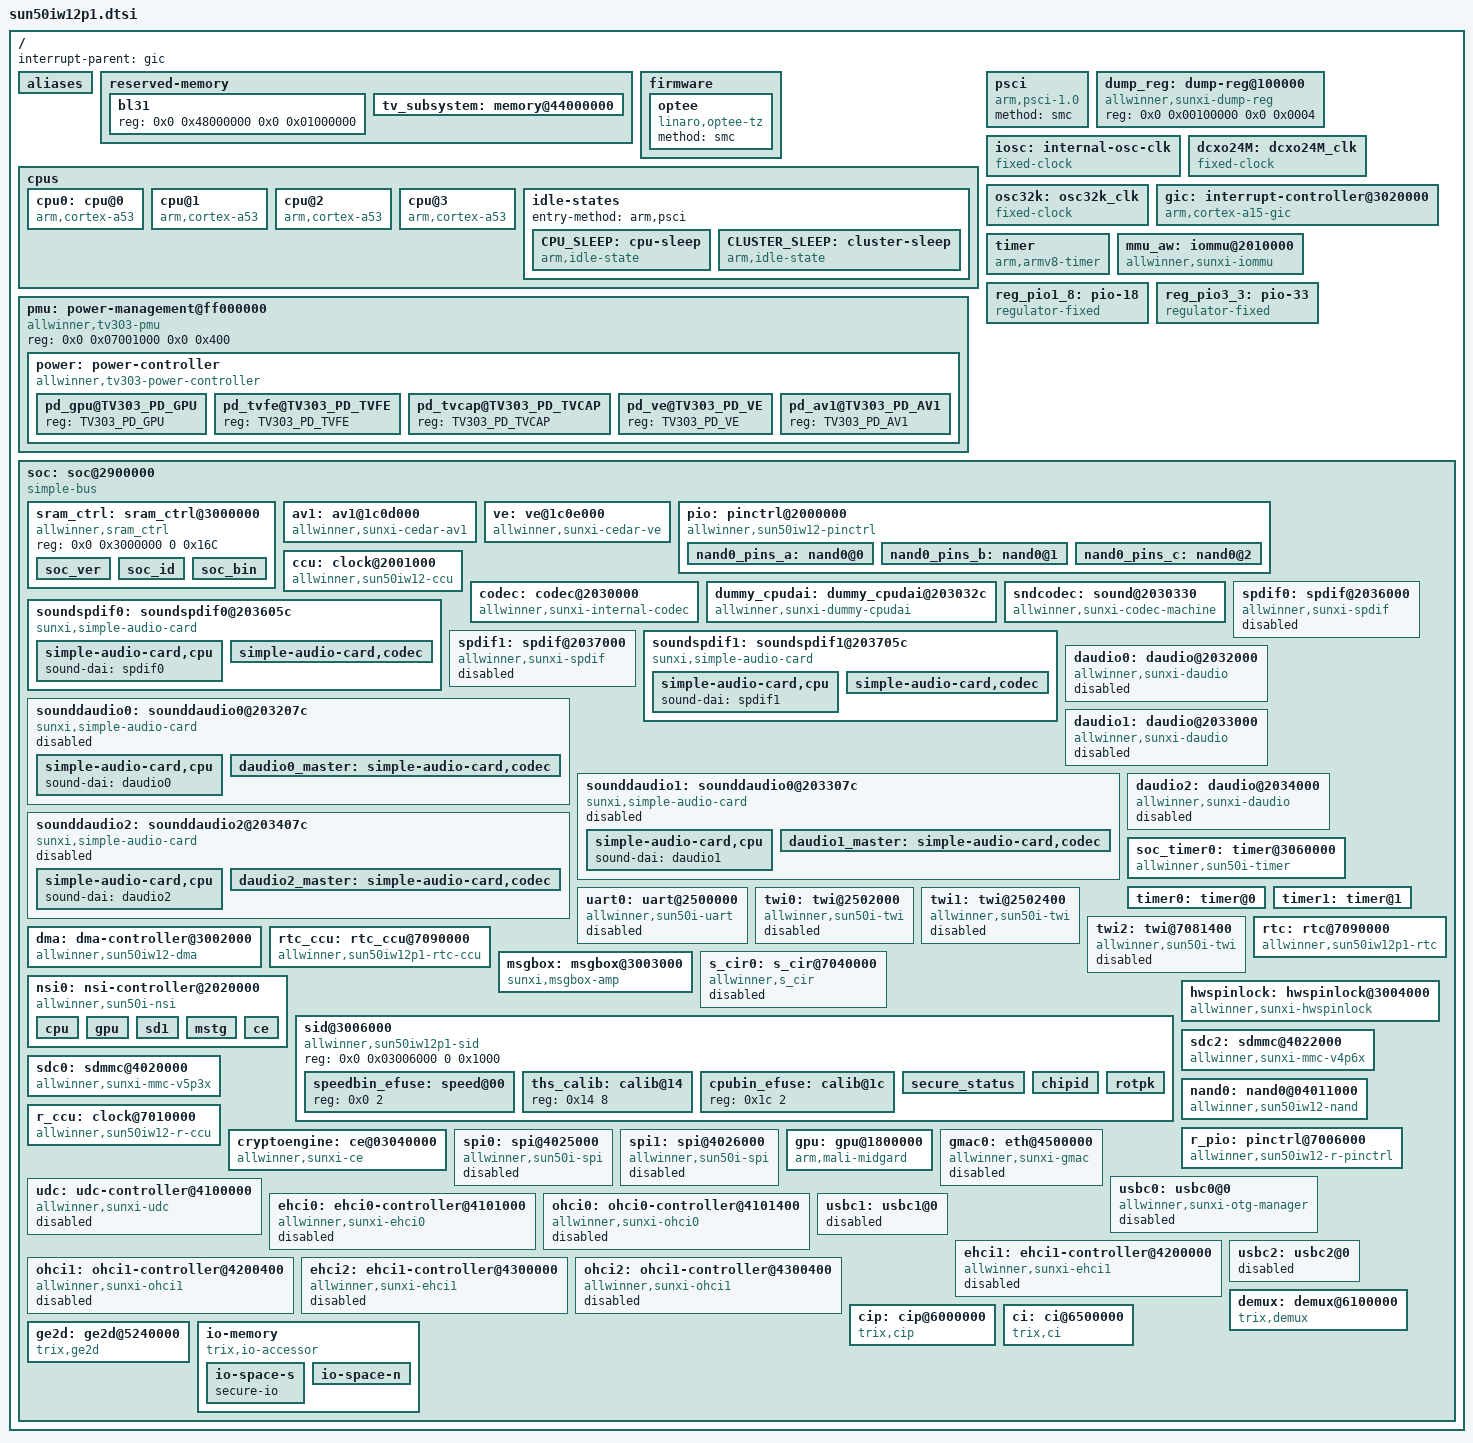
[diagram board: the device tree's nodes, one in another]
// SPDX-License-Identifier: (GPL-2.0+ or MIT)
/*
 * Copyright (C) 2020 frank@allwinnertech.com
 */

/dts-v1/;

#include <dt-bindings/clock/sun50iw12-ccu.h>
#include <dt-bindings/clock/sun50iw12-r-ccu.h>
#include <dt-bindings/clock/sun50iw12-rtc.h>
#include <dt-bindings/gpio/gpio.h>
#include <dt-bindings/gpio/sun4i-gpio.h>
#include <dt-bindings/interrupt-controller/arm-gic.h>
#include <dt-bindings/reset/sun50iw12-ccu.h>
#include <dt-bindings/reset/sun50iw12-r-ccu.h>
#include <dt-bindings/power/tv303-power.h>

/ {
	interrupt-parent = <&gic>;
	#address-cells = <2>;
	#size-cells = <2>;

	aliases {
		spi0 = &spi0;
		spi1 = &spi1;
		twi0 = &twi0;
		twi1 = &twi1;
		twi2 = &twi2;
		nand0 =&nand0;
		global-timer0  = &soc_timer0;
		ir0  = &s_cir0;
	};

	reserved-memory {
		#address-cells = <2>;
		#size-cells = <2>;
		ranges;

		bl31 {
			reg = <0x0 0x48000000 0x0 0x01000000>;
		};

		tv_subsystem: memory@44000000 {
			reg = <0x0 0x44000000 0x0 0x04000000>;
			no-map;
		};
	};

	firmware {
		optee {
			compatible = "linaro,optee-tz";
			method = "smc";
		};
	};

	cpus {
		#address-cells = <2>;
		#size-cells = <0>;

		cpu0: cpu@0 {
			device_type = "cpu";
			compatible = "arm,cortex-a53","arm,armv8";
			reg = <0x0 0x0>;
			enable-method = "psci";
			cpu-idle-states = <&CPU_SLEEP &CLUSTER_SLEEP>;
		};

		cpu@1 {
			device_type = "cpu";
			compatible = "arm,cortex-a53","arm,armv8";
			reg = <0x0 0x1>;
			enable-method = "psci";
			cpu-idle-states = <&CPU_SLEEP &CLUSTER_SLEEP>;
		};

		cpu@2 {
			device_type = "cpu";
			compatible = "arm,cortex-a53","arm,armv8";
			reg = <0x0 0x2>;
			enable-method = "psci";
			cpu-idle-states = <&CPU_SLEEP &CLUSTER_SLEEP>;
		};

		cpu@3 {
			device_type = "cpu";
			compatible = "arm,cortex-a53","arm,armv8";
			reg = <0x0 0x3>;
			enable-method = "psci";
			cpu-idle-states = <&CPU_SLEEP &CLUSTER_SLEEP>;
		};

		idle-states {
			entry-method = "arm,psci";

			CPU_SLEEP: cpu-sleep {
				compatible = "arm,idle-state";
				arm,psci-suspend-param = <0x0010000>;
				entry-latency-us = <46>;
				exit-latency-us = <59>;
				min-residency-us = <110000>;
				local-timer-stop;
			};

			CLUSTER_SLEEP: cluster-sleep {
				compatible = "arm,idle-state";
				arm,psci-suspend-param = <0x1010000>;
				entry-latency-us = <47>;
				exit-latency-us = <74>;
				min-residency-us = <160000>;
				local-timer-stop;
			};
		};
	};

	psci {
		compatible = "arm,psci-1.0";
		method = "smc";
	};

	dump_reg: dump-reg@100000 {
		compatible = "allwinner,sunxi-dump-reg";
		reg = <0x0 0x00100000 0x0 0x0004>;
	};

	iosc: internal-osc-clk {
		#clock-cells = <0>;
		compatible = "fixed-clock";
		clock-frequency = <16000000>;
		clock-accuracy = <300000000>;
		clock-output-names = "iosc";
	};

	dcxo24M: dcxo24M_clk {
		#clock-cells = <0>;
		compatible = "fixed-clock";
		clock-frequency = <24000000>;
		clock-output-names = "dcxo24M";
	};

	osc32k: osc32k_clk {
		#clock-cells = <0>;
		compatible = "fixed-clock";
		clock-frequency = <32768>;
		clock-output-names = "osc32k";
	};

	gic: interrupt-controller@3020000 {
		compatible = "arm,cortex-a15-gic", "arm,cortex-a9-gic";
		#interrupt-cells = <3>;
		#address-cells = <0>;
		interrupt-controller;
		reg = <0x0 0x03021000 0 0x1000>, /* GIC Dist */
		      <0x0 0x03022000 0 0x2000>, /* GIC CPU */
		      <0x0 0x03024000 0 0x2000>, /* GIC VCPU Control */
		      <0x0 0x03026000 0 0x2000>; /* GIC VCPU */
		interrupts = <GIC_PPI 9 0xf04>;  /* GIC Maintenence IRQ */
		interrupt-parent = <&gic>;
	};

	timer {
		compatible = "arm,armv8-timer";
		interrupts = <GIC_PPI 13
			(GIC_CPU_MASK_SIMPLE(4) | IRQ_TYPE_LEVEL_HIGH)>,
			     <GIC_PPI 14
			(GIC_CPU_MASK_SIMPLE(4) | IRQ_TYPE_LEVEL_HIGH)>,
			     <GIC_PPI 11
			(GIC_CPU_MASK_SIMPLE(4) | IRQ_TYPE_LEVEL_HIGH)>,
			     <GIC_PPI 10
			(GIC_CPU_MASK_SIMPLE(4) | IRQ_TYPE_LEVEL_HIGH)>;
		arm,no-tick-in-suspend;
	};

	mmu_aw: iommu@2010000 {
		compatible = "allwinner,sunxi-iommu";
		reg = <0x0 0x02010000 0x0 0x1000>;
		interrupts = <GIC_SPI 71 IRQ_TYPE_LEVEL_HIGH>;
		interrupt-names = "iommu-irq";
		clocks = <&ccu CLK_BUS_IOMMU>;
		clock-names = "iommu";
		#iommu-cells = <2>;
	};

	pmu: power-management@ff000000 {
		compatible = "allwinner,tv303-pmu", "syscon", "simple-mfd";
		reg = <0x0 0x07001000 0x0 0x400>;

		power: power-controller {
			compatible = "allwinner,tv303-power-controller";
			clocks = <&r_ccu CLK_R_APB1_BUS_PPU>;
			clock-names = "ppu";
			resets = <&r_ccu RST_R_APB1_BUS_PPU>;
			reset-names = "ppu_rst";
			#power-domain-cells = <1>;
			#address-cells = <1>;
			#size-cells = <0>;

			/* These power domains are grouped by VD_LOGIC */
			pd_gpu@TV303_PD_GPU {
				reg = <TV303_PD_GPU>;
			};
			pd_tvfe@TV303_PD_TVFE {
				reg = <TV303_PD_TVFE>;
			};
			pd_tvcap@TV303_PD_TVCAP {
				reg = <TV303_PD_TVCAP>;
			};
			pd_ve@TV303_PD_VE {
				reg = <TV303_PD_VE>;
			};
			pd_av1@TV303_PD_AV1 {
				reg = <TV303_PD_AV1>;
			};
		};
	};

	reg_pio1_8: pio-18 {
		compatible = "regulator-fixed";
		regulator-name = "pio-18";
		regulator-min-microvolt = <1800000>;
		regulator-max-microvolt = <1800000>;
	};

	reg_pio3_3: pio-33 {
		compatible = "regulator-fixed";
		regulator-name = "pio-33";
		regulator-min-microvolt = <3300000>;
		regulator-max-microvolt = <3300000>;
	};

	soc: soc@2900000 {
		compatible = "simple-bus";
		#address-cells = <2>;
		#size-cells = <2>;
		ranges;

		sram_ctrl: sram_ctrl@3000000 {
			compatible = "allwinner,sram_ctrl";
			reg = <0x0 0x3000000 0 0x16C>;
			soc_ver {
				offset = <0x24>;
				mask = <0x7>;
				shift = <0>;
				ver_a = <0x18600000>;
			};

			soc_id {
				offset = <0x200>;
				mask = <0x1>;
				shift = <22>;
			};

			soc_bin {
				offset = <0x0>;
				mask = <0x3ff>;
				shift = <0x0>;
			};

		};

		av1: av1@1c0d000 {
			compatible = "allwinner,sunxi-cedar-av1";
			reg = <0x0 0x01c0d000 0x0 0x1000>,
			      <0x0 0x02001000 0x0 0x1000>;
			interrupts = <GIC_SPI 107 IRQ_TYPE_LEVEL_HIGH>;
			clocks = <&ccu CLK_BUS_VE>,
				 <&ccu CLK_BUS_AV1>,
				 <&ccu CLK_VE_CORE>,
				 <&ccu CLK_MBUS_AV1>;
			clock-names = "bus_ve", "bus_av1", "av1", "mbus_av1";
			resets = <&ccu RST_BUS_VE>,
				 <&ccu RST_BUS_AV1>;
			reset-names = "reset_ve", "reset_av1";
			iommus = <&mmu_aw 5 1>;
		};

		ve: ve@1c0e000 {
			compatible = "allwinner,sunxi-cedar-ve";
			reg = <0x0 0x01c0e000 0x0 0x1000>,
			      <0x0 0x03000000 0x0 0x10>;
			interrupts = <GIC_SPI 75 IRQ_TYPE_LEVEL_HIGH>;
			clocks = <&ccu CLK_BUS_VE>,
				 <&ccu CLK_BUS_VE3>,
				 <&ccu CLK_VE_CORE>,
				 <&ccu CLK_MBUS_VE3>;
			clock-names = "bus_ve", "bus_ve3", "ve", "mbus_ve3";
			resets = <&ccu RST_BUS_VE>,
				 <&ccu RST_BUS_VE3>;
			reset-names = "reset_ve", "reset_ve3";
			iommus = <&mmu_aw 0 1>;
		};

		pio: pinctrl@2000000 {
			compatible = "allwinner,sun50iw12-pinctrl";
			reg = <0x0 0x02000000 0x0 0x400>;
			interrupts = <GIC_SPI 54 IRQ_TYPE_LEVEL_HIGH>,
				     <GIC_SPI 55 IRQ_TYPE_LEVEL_HIGH>,
				     <GIC_SPI 56 IRQ_TYPE_LEVEL_HIGH>,
				     <GIC_SPI 57 IRQ_TYPE_LEVEL_HIGH>,
				     <GIC_SPI 58 IRQ_TYPE_LEVEL_HIGH>,
				     <GIC_SPI 59 IRQ_TYPE_LEVEL_HIGH>,
				     <GIC_SPI 60 IRQ_TYPE_LEVEL_HIGH>,
				     <GIC_SPI 61 IRQ_TYPE_LEVEL_HIGH>,
				     <GIC_SPI 62 IRQ_TYPE_LEVEL_HIGH>;
			clocks = <&ccu CLK_APB0>, <&dcxo24M>, <&osc32k>;
			clock-names = "apb", "hosc", "losc";
			gpio-controller;
			#gpio-cells = <3>;
			interrupt-controller;
			#interrupt-cells = <3>;
			vcc-pf-supply = <&reg_pio1_8>;
			vcc-pfo-supply = <&reg_pio3_3>;

			nand0_pins_a: nand0@0 {
				pins = "PC0", "PC1", "PC2", "PC5",
						 "PC8", "PC9", "PC10", "PC11",
						 "PC12", "PC13", "PC14", "PC15",
						 "PC16";
				function = "nand0";
				drive-strength = <30>;
			};

			nand0_pins_b: nand0@1 {
				pins = "PC4", "PC6", "PC3", "PC7";
				function = "nand0";
				drive-strength = <30>;
				bias-pull-up;/* only RB&CE should be pulled up */
			};

			nand0_pins_c: nand0@2 {
				pins = "PC0", "PC1", "PC2", "PC3",
						 "PC4", "PC5", "PC6", "PC7",
						 "PC8", "PC9", "PC10", "PC11",
						 "PC12", "PC13", "PC14", "PC15",
						 "PC16";
				function = "gpio_in";
			};
		};

		ccu: clock@2001000 {
			compatible = "allwinner,sun50iw12-ccu";
			reg = <0x0 0x02001000 0x0 0x1000>;
			clocks = <&dcxo24M>, <&osc32k>, <&iosc>;
			clock-names = "hosc", "losc", "iosc";
			#clock-cells = <1>;
			#reset-cells = <1>;
		};

		/* codec addr: 0x02030000, the others is invalid to avoid build warining */
		codec:codec@2030000 {
			#sound-dai-cells = <0>;
			compatible = "allwinner,sunxi-internal-codec";
			reg = <0x0 0x02030000 0x0 0x32c>,/*codec baseadress*/
			      <0x0 0x02031000 0x0 0x7c>;/*interi2s baseadress*/
			clocks = <&ccu CLK_PLL_AUDIO>,	/* 98.304M / 90.3168M */
				 <&ccu CLK_AUDIO_CODEC_DAC>,
				 <&ccu CLK_AUDIO_CODEC_ADC>,
				 <&ccu CLK_BUS_AUDIO_CODEC>;
			clock-names = "pll_audio", "codec_dac", "codec_adc",
				      "codec_bus";
			resets = <&ccu RST_BUS_AUDIO_CODEC>;
			playback_cma	= <128>;
			capture_cma	= <256>;
			device_type = "codec";
		};

		dummy_cpudai:dummy_cpudai@203032c {
			compatible = "allwinner,sunxi-dummy-cpudai";
			reg = <0x0 0x0203032c 0x0 0x4>;
			tx_fifo_size	= <128>;
			rx_fifo_size	= <256>;
			dac_txdata	= <0x02030020>;
			adc_txdata	= <0x02030040>;
			playback_cma	= <128>;
			capture_cma	= <256>;
			device_type = "cpudai";
			dmas = <&dma 7>, <&dma 7>;
			dma-names = "tx", "rx";
		};

		sndcodec:sound@2030330 {
			compatible = "allwinner,sunxi-codec-machine";
			reg = <0x0 0x02030330 0x0 0x4>;
			interrupts = <GIC_SPI 25 IRQ_TYPE_LEVEL_HIGH>;
			hp_detect_case = <0x00>;
			sunxi,audio-codec = <&codec>;
			sunxi,cpudai-controller = <&dummy_cpudai>;
			device_type = "sndcodec";
		};

		/* spdif0 addr: 0x02036000, the others is invalid to avoid build warining */
		spdif0:spdif@2036000{
			#sound-dai-cells = <0>;
			compatible = "allwinner,sunxi-spdif";
			reg = <0x0 0x02036000 0x0 0x58>;
			clocks = <&ccu CLK_PLL_AUDIO>,	/* 98.304M / 90.3168M */
				 <&ccu CLK_SPDIF0_TX>,
				 <&ccu CLK_SPDIF0_RX>,
				 <&ccu CLK_BUS_SPDIF0>;
			clock-names = "pll_audio", "spdif_tx", "spdif_rx", "spdif_bus";
			resets = <&ccu RST_BUS_SPDIF0>;
			interrupts = <GIC_SPI 23 IRQ_TYPE_LEVEL_HIGH>;
			pinctrl-names = "default","sleep";
			device_type = "spdif0";
			dmas = <&dma 2>, <&dma 2>;
			dma-names = "tx", "rx";
			status = "disabled";
		};

		/* HDMI RX */
		soundspdif0:soundspdif0@203605c {
			reg = <0x0 0x0203605c 0x0 0x4>;
			compatible = "sunxi,simple-audio-card";
			simple-audio-card,name = "sndspdif0";
			 /* simple-audio-card,format = "i2s"; */
			simple-audio-card,cpu {
				sound-dai = <&spdif0>;
			};

			simple-audio-card,codec {
				/*snd-soc-dummy*/
			};
		 };

		/* spdif1 addr: 0x02037000, the others is invalid to avoid build warining */
		spdif1:spdif@2037000{
			#sound-dai-cells = <0>;
			compatible = "allwinner,sunxi-spdif";
			reg = <0x0 0x02037000 0x0 0x58>;
			clocks = <&ccu CLK_PLL_AUDIO>,	/* 98.304M / 90.3168M */
				 <&ccu CLK_SPDIF1_TX>,
				 <&ccu CLK_SPDIF1_RX>,
				 <&ccu CLK_BUS_SPDIF1>;
			clock-names = "pll_audio", "spdif_tx", "spdif_rx", "spdif_bus";
			resets = <&ccu RST_BUS_SPDIF1>;
			interrupts = <GIC_SPI 24 IRQ_TYPE_LEVEL_HIGH>;
			pinctrl-names = "default","sleep";
			device_type = "spdif1";
			dmas = <&dma 9>, <&dma 9>;
			dma-names = "tx", "rx";
			status = "disabled";
		};

		/* COMMOM USE */
		soundspdif1:soundspdif1@203705c {
			reg = <0x0 0x0203705c 0x0 0x4>;
			compatible = "sunxi,simple-audio-card";
			simple-audio-card,name = "sndspdif1";
			/* simple-audio-card,format = "i2s"; */
			simple-audio-card,cpu {
				sound-dai = <&spdif1>;
			};

			simple-audio-card,codec {
				/*snd-soc-dummy*/
			};
		 };

		/* daudio0 addr: 0x02032000, the others is invalid to avoid build warining */
		daudio0:daudio@2032000 {
			#sound-dai-cells = <0>;
			compatible = "allwinner,sunxi-daudio";
			reg = <0x0 0x02032000 0x0 0x7c>;
			clocks = <&ccu CLK_PLL_AUDIO>, /* 98.304M / 90.3168M */
				 <&ccu CLK_I2S0>,
				 <&ccu CLK_BUS_I2S0>;
			clock-names = "pll_audio", "i2s0", "i2s0_bus";
			resets = <&ccu RST_BUS_I2S0>;
			pinctrl-names = "default", "sleep";
			device_type = "daudio0";
			dmas = <&dma 3>, <&dma 3>;
			dma-names = "tx", "rx";
			status = "disabled";
		};

		sounddaudio0: sounddaudio0@203207c {
			reg = <0x0 0x0203207c 0x0 0x4>;
			compatible = "sunxi,simple-audio-card";
			simple-audio-card,name = "snddaudio0";
			simple-audio-card,format = "i2s";
			/* simple-audio-card,frame-master = <&daudio0_master>; */
			/* simple-audio-card,bitclock-master = <&daudio0_master>; */
			/* simple-audio-card,bitclock-inversion; */
			/* simple-audio-card,frame-inversion; */
			status = "disabled";
			simple-audio-card,cpu {
				sound-dai = <&daudio0>;
			};
			daudio0_master: simple-audio-card,codec {
				/* sound-dai = <&ac108>; */
			};
		};

		/* daudio1 addr: 0x02033000, the others is invalid to avoid build warining */
		daudio1:daudio@2033000 {
			#sound-dai-cells = <0>;
			compatible = "allwinner,sunxi-daudio";
			reg = <0x0 0x02033000 0x0 0x7c>;
			clocks = <&ccu CLK_PLL_AUDIO>, /* 98.304M / 90.3168M */
				 <&ccu CLK_I2S1>,
				 <&ccu CLK_BUS_I2S1>;
			clock-names = "pll_audio", "i2s1", "i2s1_bus";
			resets = <&ccu RST_BUS_I2S1>;
			pinctrl-names = "default", "sleep";
			device_type = "daudio1";
			dmas = <&dma 4>, <&dma 4>;
			dma-names = "tx", "rx";
			status = "disabled";
		};

		sounddaudio1: sounddaudio0@203307c {
			reg = <0x0 0x0203307c 0x0 0x4>;
			compatible = "sunxi,simple-audio-card";
			simple-audio-card,name = "snddaudio1";
			simple-audio-card,format = "i2s";
			status = "disabled";
			simple-audio-card,cpu {
				sound-dai = <&daudio1>;
			};
			daudio1_master: simple-audio-card,codec {
				/* sound-dai = <&ac108>; */
			};
		};

		/* daudio2 addr: 0x02034000, the others is invalid to avoid build warining */
		daudio2:daudio@2034000 {
			#sound-dai-cells = <0>;
			compatible = "allwinner,sunxi-daudio";
			reg = <0x0 0x02034000 0x0 0x7c>;
			clocks = <&ccu CLK_PLL_AUDIO>, /* 98.304M / 90.3168M */
				 <&ccu CLK_I2S2>,
				 <&ccu CLK_BUS_I2S2>;
			clock-names = "pll_audio", "i2s2", "i2s2_bus";
			resets = <&ccu RST_BUS_I2S2>;
			pinctrl-names = "default", "sleep";
			device_type = "daudio2";
			dmas = <&dma 5>, <&dma 5>;
			dma-names = "tx", "rx";
			status = "disabled";
		};

		sounddaudio2: sounddaudio2@203407c {
			reg = <0x0 0x0203407c 0x0 0x4>;
			compatible = "sunxi,simple-audio-card";
			simple-audio-card,name = "snddaudio2";
			simple-audio-card,format = "i2s";
			status = "disabled";
			simple-audio-card,cpu {
				sound-dai = <&daudio2>;
			};
			daudio2_master: simple-audio-card,codec {
				 /* snd-soc-dummy */
			};
		 };

		soc_timer0: timer@3060000 {
			compatible = "allwinner,sun50i-timer";
			device_type = "soc_timer";
			reg = <0x0 0x03060000 0x0 0xA0>;
			interrupt-parent = <&gic>;
			interrupts = <GIC_SPI 48 IRQ_TYPE_LEVEL_HIGH>;
			sunxi-timers = <&timer0>, <&timer1>;
		};

		timer0: timer@0 {
			clocks = <&dcxo24M>, <&ccu CLK_TIMER0>, <&ccu CLK_BUS_TIMER0>;
			clock-names = "parent", "mod", "bus";
			resets = <&ccu RST_BUS_TIMER0>;
		};

		timer1: timer@1 {
			clocks = <&dcxo24M>, <&ccu CLK_TIMER1>, <&ccu CLK_BUS_TIMER0>;
			clock-names = "parent", "mod", "bus";
		};

		uart0: uart@2500000 {
			compatible = "allwinner,sun50i-uart";
			reg = <0x0 0x02500000 0x0 0x400>;
			interrupts = <GIC_SPI 0 IRQ_TYPE_LEVEL_HIGH>;
			clocks = <&ccu CLK_BUS_UART0>;
			/* TODO add resets */
			uart0_port = <0>;
			uart0_type = <2>;
			status = "disabled";
		};

		twi0: twi@2502000{
			#address-cells = <1>;
			#size-cells = <0>;
			compatible = "allwinner,sun50i-twi";
			device_type = "twi0";
			reg = <0x0 0x02502000 0x0 0x400>;
			interrupts = <GIC_SPI 7 IRQ_TYPE_LEVEL_HIGH>;
			clocks = <&ccu CLK_BUS_I2C0>;
			resets = <&ccu RST_BUS_I2C0>;
			clock-names = "bus";
			status = "disabled";
		};

		twi1: twi@2502400{
			#address-cells = <1>;
			#size-cells = <0>;
			compatible = "allwinner,sun50i-twi";
			device_type = "twi1";
			reg = <0x0 0x2502400 0x0 0x400>;
			interrupts = <GIC_SPI 8 IRQ_TYPE_LEVEL_HIGH>;
			clocks = <&ccu CLK_BUS_I2C1>;
			resets = <&ccu RST_BUS_I2C1>;
			clock-names = "bus";
			status = "disabled";
		};

		twi2: twi@7081400{
			#address-cells = <1>;
			#size-cells = <0>;
			compatible = "allwinner,sun50i-twi";
			device_type = "s_twi0";
			reg = <0x0 0x07081400 0x0 0x400>;
			interrupts = <GIC_SPI 153 IRQ_TYPE_LEVEL_HIGH>;
			clocks = <&ccu CLK_R_APB1_BUS_I2C0>;
			resets = <&ccu RST_R_APB1_BUS_I2C0>;
			clock-names = "bus";
			status = "disabled";
		};

		dma: dma-controller@3002000 {
			compatible = "allwinner,sun50iw12-dma";
			reg = <0x0 0x03002000 0x0 0x1000>;
			interrupts = <GIC_SPI 45 IRQ_TYPE_LEVEL_HIGH>;
			clocks = <&ccu CLK_BUS_DMA>, <&ccu CLK_MBUS_DMA>;
			clock-names = "bus", "mbus";
			dma-channels = <16>;
			dma-requests = <54>;
			resets = <&ccu RST_BUS_DMA>;
			#dma-cells = <1>;
		};

		rtc: rtc@7090000 {
			compatible = "allwinner,sun50iw12p1-rtc";
			device_type = "rtc";
			wakeup-source;
			reg = <0x0 0x07090000 0x0 0x200>;
			interrupts = <GIC_SPI 147 IRQ_TYPE_LEVEL_HIGH>;
			clocks = <&r_ccu CLK_R_AHB_BUS_RTC>, <&rtc_ccu CLK_RTC_1K>;
			clock-names = "r-ahb-rtc", "rtc-1k";
			resets = <&r_ccu RST_R_AHB_BUS_RTC>;
			gpr_offset = <0x100>;
			gpr_len = <8>;
			gpr_cur_pos = <6>;
		};

		rtc_ccu: rtc_ccu@7090000 {
			compatible = "allwinner,sun50iw12p1-rtc-ccu";
			device_type = "rtc-ccu";
			reg = <0x0 0x07090000 0x0 0x200>;
			#clock-cells = <1>;
			clock-output-names = "dcxo24M-out", "iosc", "osc32k",
					     "osc32k-out", "rtc-1k";
		};

		msgbox: msgbox@3003000 {
			compatible = "sunxi,msgbox-amp";
			reg = <0x0 0x03003000 0x0 0x400>,
			      <0x0 0x03003400 0x0 0x400>,
			      <0x0 0x03003800 0x0 0x400>;
			interrupts = <GIC_SPI 46 IRQ_TYPE_LEVEL_HIGH>,
					<GIC_SPI 109 IRQ_TYPE_LEVEL_HIGH>,
					<GIC_SPI 108 IRQ_TYPE_LEVEL_HIGH>;
			clocks = <&ccu CLK_MSGBOX>;
			rpmsg_id = "sunxi,mips-msgbox",
				   "sunxi,cpus-msgbox";
			resets = <&ccu RST_BUS_MSGBOX>;
			reset-names = "rst";
			msgbox_amp_counts = <3>;
			msgbox_amp_local = <0>;
			rpmsg_amp_remote-0 = <2>;
			rpmsg_read_channel-0 = <1>;
			rpmsg_write_channel-0 = <1>;
			rpmsg_amp_remote-1 = <1>;
			rpmsg_read_channel-1 = <1>;
			rpmsg_write_channel-1 = <1>;
		};

		s_cir0: s_cir@7040000 {
			compatible = "allwinner,s_cir";
			reg = <0x0 0x07040000 0x0 0x400>;
			interrupts = <GIC_SPI 155 IRQ_TYPE_LEVEL_HIGH>;
			clocks = <&r_ccu CLK_R_APB0_BUS_IR>, <&dcxo24M>, <&r_ccu CLK_R_APB0_IR>;
			clock-names = "bus", "pclk", "mclk";
			resets = <&r_ccu RST_R_APB0_BUS_IR_RX>;
			supply = "";
			supply_vol = "";
			status = "disabled";
		};

		nsi0:nsi-controller@2020000 {
			compatible = "allwinner,sun50i-nsi";
			interrupts = <GIC_SPI 63 IRQ_TYPE_LEVEL_HIGH>;
			reg = <0x0 0x02020000 0x0 0x10000>;
			clocks = <&ccu CLK_PLL_PERIPH0_2X>, <&ccu CLK_MBUS>;
			clock-names = "pll", "bus";
			resets = <&ccu RST_MBUS>;
			clock-frequency = <400000000>;
			#nsi-cells = <1>;
			cpu{
				mode = <0>; /*dont't set cpu mode*/
				pri = <0>;
				select = <0>;
			};
			gpu{
				mode = <0>;
				pri = <3>;
				select = <1>;
			};
			sd1{
				mode = <1>;
				pri = <2>;
				select = <0>;
			};
			mstg{
				mode = <0>;
				pri = <1>;
				select = <0>;
			};
			ce{
				mode = <1>;
				pri = <0>;
				select = <1>;
			};
		};

		sid@3006000 {
			compatible = "allwinner,sun50iw12p1-sid", "allwinner,sunxi-sid";
			reg = <0x0 0x03006000 0 0x1000>;
			#address-cells = <1>;
			#size-cells = <1>;

			speedbin_efuse: speed@00 {
				reg = <0x0 2>;
			};

			ths_calib: calib@14 {
				reg = <0x14 8>;
			};

			cpubin_efuse: calib@1c {
				reg = <0x1c 2>;
			};

			/* some guys has nothing to do with nvmem */
			secure_status {
				reg = <0x0 0>;
				offset = <0xa0>;
				size = <0x4>;
			};
			chipid {
				reg = <0x0 0>;
				offset = <0x200>;
				size = <0x10>;
			};
			rotpk {
				reg = <0x0 0>;
				offset = <0x270>;
				size = <0x20>;
			};
		};

		hwspinlock: hwspinlock@3004000 {
			compatible = "allwinner,sunxi-hwspinlock";
			clocks = <&ccu CLK_SPINLOCK>;
			clock-names = "clk_hwspinlock_bus";
			resets = <&ccu RST_BUS_SPINLOCK>;
			reg = <0x0 0x03004000 0x0 0x1000>;
			/* the number hwspinlock we needed, max 32 */
			num-locks = <32>;
		};

		sdc2: sdmmc@4022000 {
			compatible = "allwinner,sunxi-mmc-v4p6x";
			device_type = "sdc2";
			reg = <0x0 0x04022000 0x0 0x1000>;
			interrupts = <GIC_SPI 41 IRQ_TYPE_LEVEL_HIGH>;
			clocks = <&dcxo24M>,
				 <&ccu CLK_PLL_PERIPH1_2X>,
				 <&ccu CLK_MMC2>,
				 <&ccu CLK_BUS_MMC2>;
			clock-names = "osc24m","pll_periph","mmc","ahb";
			resets = <&ccu RST_BUS_MMC2>;
			reset-names = "rst";
			bus-width = <4>;
			req-page-count = <2>;
			cap-mmc-highspeed;
			cap-cmd23;
			mmc-cache-ctrl;
			non-removable;
			/*max-frequency = <200000000>;*/
			max-frequency = <50000000>;
			cap-erase;
			mmc-high-capacity-erase-size;
			no-sdio;
			no-sd;
			/*-- speed mode --*/
			/*sm0: DS26_SDR12*/
			/*sm1: HSSDR52_SDR25*/
			/*sm2: HSDDR52_DDR50*/
		/*sm3: HS200_SDR104*/
			/*sm4: HS400*/
			/*-- frequency point --*/
			/*f0: CLK_400K*/
			/*f1: CLK_25M*/
			/*f2: CLK_50M*/
			/*f3: CLK_100M*/
			/*f4: CLK_150M*/
			/*f5: CLK_200M*/

			sdc_tm4_sm0_freq0 = <0>;
			sdc_tm4_sm0_freq1 = <0>;
			sdc_tm4_sm1_freq0 = <0x00000000>;
			sdc_tm4_sm1_freq1 = <0>;
			sdc_tm4_sm2_freq0 = <0x00000000>;
			sdc_tm4_sm2_freq1 = <0>;
			sdc_tm4_sm3_freq0 = <0x05000000>;
			sdc_tm4_sm3_freq1 = <0x00000005>;
			sdc_tm4_sm4_freq0 = <0x00050000>;
			sdc_tm4_sm4_freq1 = <0x00000004>;
			sdc_tm4_sm4_freq0_cmd = <0>;
			sdc_tm4_sm4_freq1_cmd = <0>;

			/*vmmc-supply = <&reg_3p3v>;*/
			/*vqmc-supply = <&reg_3p3v>;*/
			/*vdmc-supply = <&reg_3p3v>;*/
			/*vmmc = "vcc-card";*/
			/*vqmc = "";*/
			/*vdmc = "";*/
			/*sunxi-power-save-mode;*/
		};

		sdc0: sdmmc@4020000 {
			compatible = "allwinner,sunxi-mmc-v5p3x";
			device_type = "sdc0";
			reg = <0x0 0x04020000 0x0 0x1000>;
			interrupts = <GIC_SPI 39 IRQ_TYPE_LEVEL_HIGH>;
			clocks = <&dcxo24M>,
				 <&ccu CLK_PLL_PERIPH1_2X>,
				 <&ccu CLK_MMC0>,
				 <&ccu CLK_BUS_MMC0>;
			clock-names = "osc24m","pll_periph","mmc","ahb";
			resets = <&ccu RST_BUS_MMC0>;
			reset-names = "rst";
		};

		nand0:nand0@04011000 {
			compatible = "allwinner,sun50iw12-nand";
			device_type = "nand0";
			reg = <0x0 0x04011000 0x0 0x1000>;/* nand0 */
			interrupts = <GIC_SPI 38 IRQ_TYPE_LEVEL_HIGH>;
			clocks = <&ccu CLK_PLL_PERIPH1_2X>,
				<&ccu CLK_NAND0>,
				 <&ccu CLK_NAND1>,
				 <&ccu CLK_BUS_NAND>,
				 <&ccu CLK_MBUS_NAND>;
			clock-names = "pll_periph","mclk","ecc", "bus", "mbus";
			resets = <&ccu RST_BUS_NAND>;
			reset-names = "rst";

			pinctrl-names = "default", "sleep";
			pinctrl-0 = <&nand0_pins_a &nand0_pins_b>;
			pinctrl-1 = <&nand0_pins_c>;

			nand0_regulator1 = "none";
			nand0_regulator2 = "none";
			nand0_cache_level = <0x55aaaa55>;
			nand0_flush_cache_num = <0x55aaaa55>;
			nand0_capacity_level = <0x55aaaa55>;
			nand0_id_number_ctl = <0x55aaaa55>;
			nand0_print_level = <0x55aaaa55>;
			nand0_p0 = <0x55aaaa55>;
			nand0_p1 = <0x55aaaa55>;
			nand0_p2 = <0x55aaaa55>;
			nand0_p3 = <0x55aaaa55>;
			chip_code = "sun50iw10";
			status = "okay";
			boot_crc = "disabled";
		};

		r_ccu: clock@7010000 {
			compatible = "allwinner,sun50iw12-r-ccu";
			reg = <0x0 0x07010000 0x0 0x240>;
			clocks = <&dcxo24M>, <&osc32k>, <&iosc>,
				 <&ccu CLK_PLL_PERIPH0>;
			clock-names = "hosc", "losc", "iosc", "pll-periph";
			#clock-cells = <1>;
			#reset-cells = <1>;
		};

		r_pio: pinctrl@7006000 {
			compatible = "allwinner,sun50iw12-r-pinctrl";
			reg = <0x0 0x07006000 0x0 0x400>;
			interrupts = <GIC_SPI 148 IRQ_TYPE_LEVEL_HIGH>;
			/* FIXME */
			clocks = <&r_ccu CLK_R_APB0>, <&dcxo24M>, <&osc32k>;
			clock-names = "apb", "hosc", "losc";
			gpio-controller;
			#gpio-cells = <3>;
			interrupt-controller;
			#interrupt-cells = <3>;
		};

		cryptoengine: ce@03040000 {
			compatible = "allwinner,sunxi-ce";
			device_name = "ce";
			reg = <0x0 0x03040000 0x0 0xa0>, /* non-secure space */
			      <0x0 0x03040800 0x0 0xa0>; /* secure space */
			interrupts = <GIC_SPI 73 IRQ_TYPE_EDGE_RISING>, /*non-secure*/
				   <GIC_SPI 74 IRQ_TYPE_EDGE_RISING>; /* secure*/
			clock-frequency = <400000000>; /* 400MHz */
			clocks = <&ccu CLK_BUS_CE>, <&ccu CLK_CE>, <&ccu CLK_MBUS_CE>,
					<&ccu CLK_PLL_PERIPH0_2X>;
			clock-names = "bus_ce", "ce_clk", "mbus_ce", "pll_periph0_2x";
			resets = <&ccu RST_BUS_CE>;
			status = "okay";
		};

		spi0: spi@4025000 {
			#address-cells = <1>;
			#size-cells = <0>;
			compatible = "allwinner,sun50i-spi";
			device_type = "spi0";
			reg = <0x0 0x04025000 0x0 0x300>;
			interrupts = <GIC_SPI 13 IRQ_TYPE_LEVEL_HIGH>;
			clocks = <&ccu CLK_PLL_PERIPH0>, <&ccu CLK_SPI0>,
				 <&ccu CLK_BUS_SPI0>;
			clock-names = "pll", "mod", "bus";
			resets = <&ccu RST_BUS_SPI0>;
			clock-frequency = <100000000>;
			pinctrl-names = "default", "sleep";
			spi0_cs_number = <1>;
			spi0_cs_bitmap = <1>;
			dmas = <&dma 22>, <&dma 22>;
			dma-names = "tx", "rx";
			status = "disabled";
		};

		spi1: spi@4026000 {
			#address-cells = <1>;
			#size-cells = <0>;
			compatible = "allwinner,sun50i-spi";
			device_type = "spi1";
			reg = <0x0 0x04026000 0x0 0x300>;
			interrupts = <GIC_SPI 14 IRQ_TYPE_LEVEL_HIGH>;
			clocks = <&ccu CLK_PLL_PERIPH0>, <&ccu CLK_SPI1>,
				 <&ccu CLK_BUS_SPI1>;
			clock-names = "pll", "mod", "bus";
			resets = <&ccu RST_BUS_SPI1>;
			clock-frequency = <100000000>;
			pinctrl-names = "default", "sleep";
			spi1_cs_number = <1>;
			spi1_cs_bitmap = <1>;
			status = "disabled";
		};
		gpu: gpu@1800000 {
			device_type = "gpu";
			compatible = "arm,mali-midgard";
			reg = <0x0 0x01800000 0x0 0x10000>;
			interrupts = <GIC_SPI 117 IRQ_TYPE_LEVEL_HIGH>,
				     <GIC_SPI 118 IRQ_TYPE_LEVEL_HIGH>,
				     <GIC_SPI 76 IRQ_TYPE_LEVEL_HIGH>;
			interrupt-names = "JOB", "MMU", "GPU";
			clocks = <&ccu CLK_PLL_GPU>, <&ccu CLK_GPU>,
				 /*<&ccu CLK_GPU1>,*/<&ccu CLK_BUS_GPU>;
			clock-names = "clk_parent", "clk_mali",
				     /* "clk_bak",*/ "clk_bus";
			resets = <&ccu RST_BUS_GPU>;
			/*#cooling-cells = <2>;
			ipa_dvfs:ipa_dvfs {
				compatible = "arm,mali-simple-power-model";
				static-coefficient = <17000>;
				dynamic-coefficient = <750>;
				ts = <254682 9576 0xffffff98 4>;
				thermal-zone = "gpu-thermal-zone";
				ss-coefficient = <36>;
				ff-coefficient = <291>;
			};*/
		};

		gmac0: eth@4500000 {
			compatible = "allwinner,sunxi-gmac";
			reg = <0x0 0x04500000 0x0 0x10000>,
			      <0x0 0x03000030 0x0 0x4>;
			interrupts = <GIC_SPI 16 IRQ_TYPE_LEVEL_HIGH>;
			interrupt-names = "gmacirq";
			clocks = <&ccu CLK_BUS_EMAC>, <&ccu CLK_EMAC_25M>;
			clock-names = "gmac", "ephy";
			resets = <&ccu RST_BUS_EMAC>;
			device_type = "gmac0";
			gmac-power0;
			gmac-power1;
			gmac-power2;
			status = "disabled";
		};

		usbc0:usbc0@0 {
			device_type = "usbc0";
			compatible = "allwinner,sunxi-otg-manager";
			usb_port_type = <2>;
			usb_detect_type = <1>;
			usb_detect_mode = <0>;
			usb_id_gpio;
			usb_det_vbus_gpio;
			usb_regulator_io = "nocare";
			usb_wakeup_suspend = <0>;
			usb_luns = <3>;
			usb_serial_unique = <0>;
			usb_serial_number = "20080411";
			rndis_wceis = <1>;
			status = "disable";
		};

		udc:udc-controller@4100000 {
			compatible = "allwinner,sunxi-udc";
			reg = <0x0 0x04100000 0x0 0x1000>, /*udc base*/
			      <0x0 0x00000000 0x0 0x100>; /*sram base*/
			interrupts = <GIC_SPI 32 IRQ_TYPE_LEVEL_HIGH>;
			clocks = <&ccu CLK_BUS_OTG>;
			clock-names = "bus_otg";
			resets = <&ccu RST_BUS_OTG>, <&ccu RST_USB_PHY0>;
			reset-names = "otg", "phy";
			status = "disable";
		};

		ehci0:ehci0-controller@4101000 {
			compatible = "allwinner,sunxi-ehci0";
			reg = <0x0 0x04101000 0x0 0xFFF>, /*hci0 base*/
			      <0x0 0x00000000 0x0 0x100>, /*sram base*/
			      <0x0 0x04100000 0x0 0x1000>; /*otg base*/
			interrupts = <GIC_SPI 30 IRQ_TYPE_LEVEL_HIGH>;
			clocks = <&ccu CLK_BUS_EHCI0>;
			clock-names = "bus_hci";
			resets = <&ccu RST_BUS_EHCI0>, <&ccu RST_USB_PHY0>;
			reset-names = "hci", "phy";
			hci_ctrl_no = <0>;
			status = "disable";
		};

		ohci0:ohci0-controller@4101400 {
			compatible = "allwinner,sunxi-ohci0";
			reg = <0x0 0x04101400 0x0 0xFFF>, /*hci0 base*/
			      <0x0 0x00000000 0x0 0x100>, /*sram base*/
			      <0x0 0x04100000 0x0 0x1000>; /*otg base*/
			interrupts = <GIC_SPI 31 IRQ_TYPE_LEVEL_HIGH>;
			clocks = <&ccu CLK_BUS_OHCI0>, <&ccu CLK_USB_OHCI0>;
			clock-names = "bus_hci", "ohci";
			resets = <&ccu RST_BUS_OHCI0>, <&ccu RST_USB_PHY0>;
			reset-names = "hci", "phy";
			hci_ctrl_no = <0>;
			status = "disable";
		};

		usbc1:usbc1@0 {
			device_type = "usbc1";
			usb_regulator_io = "nocare";
			usb_wakeup_suspend = <0>;
			status = "disable";
		};

		ehci1:ehci1-controller@4200000 {
			compatible = "allwinner,sunxi-ehci1";
			reg = <0x0 0x04200000 0x0 0xFFF>, /*ehci1 base*/
			      <0x0 0x00000000 0x0 0x100>, /*sram base*/
			      <0x0 0x04100000 0x0 0x1000>; /*otg base*/
			interrupts = <GIC_SPI 33 IRQ_TYPE_LEVEL_HIGH>;
			clocks = <&ccu CLK_BUS_EHCI1>;
			clock-names = "bus_hci";
			resets = <&ccu RST_BUS_EHCI1>, <&ccu RST_USB_PHY1>;
			reset-names = "hci", "phy";
			hci_ctrl_no = <1>;
			status = "disable";
		};

		ohci1:ohci1-controller@4200400 {
			compatible = "allwinner,sunxi-ohci1";
			reg = <0x0 0x04200400 0x0 0xFFF>, /*ohci1 base*/
			      <0x0 0x00000000 0x0 0x100>, /*sram base*/
			      <0x0 0x04100000 0x0 0x1000>; /*otg base*/
			interrupts = <GIC_SPI 34 IRQ_TYPE_LEVEL_HIGH>;
			clocks = <&ccu CLK_BUS_OHCI1>, <&ccu CLK_USB_OHCI1>;
			clock-names = "bus_hci", "ohci";
			resets = <&ccu RST_BUS_OHCI1>, <&ccu RST_USB_PHY1>;
			reset-names = "hci", "phy";
			hci_ctrl_no = <1>;
			status = "disable";
		};

		usbc2:usbc2@0 {
			device_type = "usbc2";
			usb_regulator_io = "nocare";
			usb_wakeup_suspend = <0>;
			status = "disable";
		};

		ehci2:ehci1-controller@4300000 {
			compatible = "allwinner,sunxi-ehci1";
			reg = <0x0 0x04300000 0x0 0xFFF>, /*ehci1 base*/
			      <0x0 0x00000000 0x0 0x100>, /*sram base*/
			      <0x0 0x04100000 0x0 0x1000>; /*otg base*/
			interrupts = <GIC_SPI 35 IRQ_TYPE_LEVEL_HIGH>;
			clocks = <&ccu CLK_BUS_EHCI2>;
			clock-names = "bus_hci";
			resets = <&ccu RST_BUS_EHCI2>, <&ccu RST_USB_PHY2>;
			reset-names = "hci", "phy";
			hci_ctrl_no = <1>;
			status = "disable";
		};

		ohci2:ohci1-controller@4300400 {
			compatible = "allwinner,sunxi-ohci1";
			reg = <0x0 0x04300400 0x0 0xFFF>, /*ohci1 base*/
			      <0x0 0x00000000 0x0 0x100>, /*sram base*/
			      <0x0 0x04100000 0x0 0x1000>; /*otg base*/
			interrupts = <GIC_SPI 36 IRQ_TYPE_LEVEL_HIGH>;
			clocks = <&ccu CLK_BUS_OHCI2>, <&ccu CLK_USB_OHCI2>;
			clock-names = "bus_hci", "ohci";
			resets = <&ccu RST_BUS_OHCI2>, <&ccu RST_USB_PHY2>;
			reset-names = "hci", "phy";
			hci_ctrl_no = <1>;
			status = "disable";
		};

		demux: demux@6100000 {
			compatible = "trix,demux";
			reg = <0x0 0x06100000 0x0 0x00020000>;
			interrupts = <GIC_SPI 88 IRQ_TYPE_EDGE_RISING>, /*demux tsp */
					<GIC_SPI 89 IRQ_TYPE_EDGE_RISING>,		/*demux tsr */
					<GIC_SPI 91 IRQ_TYPE_EDGE_RISING>,		/*demux vsmdma 0, 1*/
					<GIC_SPI 92 IRQ_TYPE_EDGE_RISING>;
		};

		cip: cip@6000000 {
			compatible = "trix,cip";
			reg = <0x0 0x06000000 0x0 0x00020000>;
			interrupts = <GIC_SPI 78 IRQ_TYPE_EDGE_RISING>, /*cip tsp 0, 1*/
					<GIC_SPI 82 IRQ_TYPE_EDGE_RISING>,      /*cip vsmdma 0, 1*/
					<GIC_SPI 83 IRQ_TYPE_EDGE_RISING>;

		};

		ci: ci@6500000 {
			compatible = "trix,ci";
			reg = <0x0 0x06500000 0x0 0x00001000>;
			interrupts = <GIC_SPI 105 IRQ_TYPE_EDGE_RISING>;

		};

		ge2d: ge2d@5240000 {
			compatible = "trix,ge2d";
			reg = <0x0 0x05240000 0x0 0x00060000>,
				  <0x0 0x051C0000 0x0 0x00010000>,
				  <0x0 0x05200000 0x0 0x00001000>,
			      <0x0 0x05600000 0x0 0x00001000>;
			interrupts = <GIC_SPI 101 IRQ_TYPE_EDGE_RISING>;  /*svp osd vsync*/
		};

		io-memory {
			compatible = "trix,io-accessor";
			#address-cells = <2>;
			#size-cells = <2>;
			ranges;

			/* secure io space */
			io-space-s {
				secure-io;
			};

			/* non-secure io space */
			io-space-n {
				reg = <0x0 0x06000000 0x0 0x00020000>,/* cip   */
					<0x0 0x06100000 0x0 0x00020000>,  /* demux */
					<0x0 0x06500000 0x0 0x00001000>,  /* ci    */
					<0x0 0x05240000 0x0 0x00010000>,  /* ge2d  */
					<0x0 0x051C0000 0x0 0x00010000>,
					<0x0 0x05200000 0x0 0x00001000>,
					<0x0 0x05600000 0x0 0x00001000>;
			};
		};
	};
};
